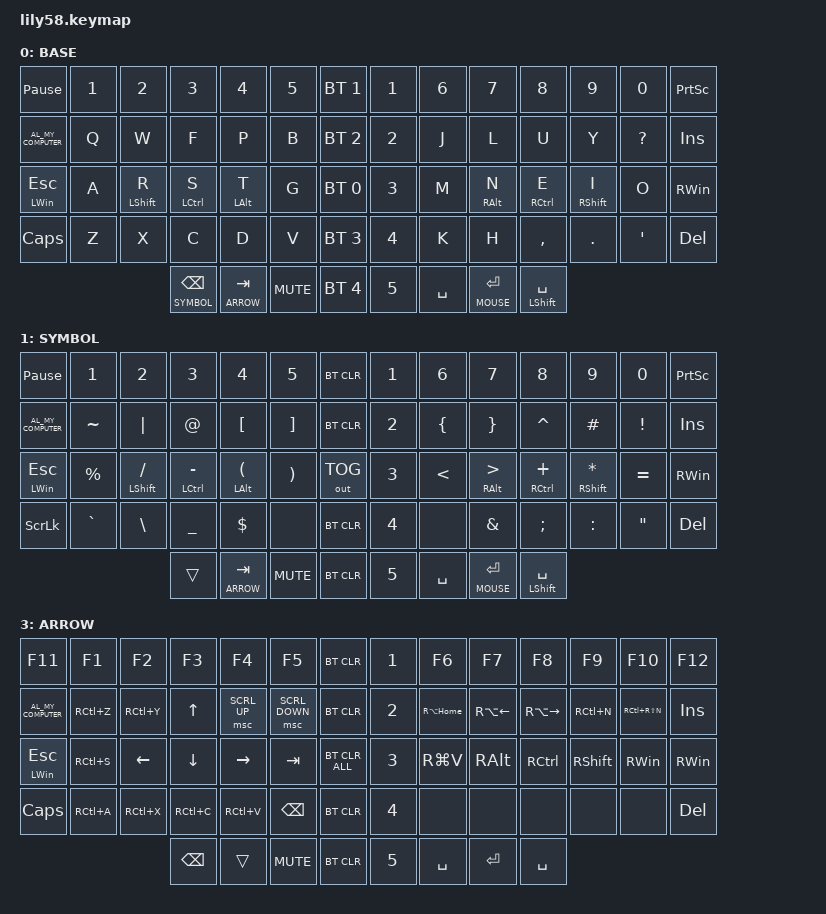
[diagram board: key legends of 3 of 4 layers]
#include <behaviors.dtsi>
#include <dt-bindings/zmk/keys.h>
#include <dt-bindings/zmk/bt.h>
#include <dt-bindings/zmk/rgb.h>
#include <dt-bindings/zmk/ext_power.h>
#include <dt-bindings/zmk/mouse.h>
#include <behaviors/mouse_keys.dtsi>
#include <dt-bindings/zmk/outputs.h>

&mmv {
  acceleration-exponent = <1>;      // 1
  time-to-max-speed-ms = <500>;    // 40
  delay-ms = <0>;                   // 0
};
&msc {
  acceleration-exponent = <1>;      // 0
  time-to-max-speed-ms = <40>;      // 500
  delay-ms = <0>;                   // 10
};

#define BASE 0
#define SYMBOL 1
#define MOUSE 2
#define ARROW 3


&lt {
    tapping-term-ms = <200>;
    quick-tap-ms = <200>;
};
&mt {
    tapping-term-ms = <400>;
    quick-tap-ms = <200>;
};




/ {
    keymap {
        compatible = "zmk,keymap";


        default_layer {
        display-name = "BASE";
            bindings = <
&kp PAUSE_BREAK          &kp N1     &kp N2             &kp N3                &kp N4             &kp N5       &bt BT_SEL 1                &kp N1        &kp N6       &kp N7                &kp N8                 &kp N9             &kp N0            &kp PRINTSCREEN
&kp C_AL_MY_COMPUTER     &kp Q      &kp W              &kp F                 &kp P              &kp B        &bt BT_SEL 2                &kp N2        &kp J        &kp L                 &kp U                  &kp Y              &kp QMARK         &kp INS
&mt LEFT_WIN ESC         &kp A      &mt LEFT_SHIFT R   &mt LCTRL S           &mt LEFT_ALT T     &kp G        &bt BT_SEL 0                &kp N3        &kp M        &mt RIGHT_ALT N       &mt RCTRL E            &mt RIGHT_SHIFT I  &kp O             &kp RIGHT_WIN
&kp CAPS                 &kp Z      &kp X              &kp C                 &kp D              &kp V        &bt BT_SEL 3                &kp N4        &kp K        &kp H                 &kp COMMA              &kp DOT            &kp SINGLE_QUOTE  &kp DEL
                                                       &lt SYMBOL BACKSPACE  &lt ARROW TAB      &kp C_MUTE   &bt BT_SEL 4                &kp N5        &kp SPACE    &lt MOUSE ENTER       &mt LEFT_SHIFT SPACE 
            >;
            sensor-bindings =
                <&inc_dec_kp C_VOL_DN C_VOL_UP>,
                <&inc_dec_kp RIGHT_ARROW LEFT_ARROW>;
        };



        lower_layer {
        display-name = "SYMBOL";
            bindings = <
&kp PAUSE_BREAK          &kp N1     &kp N2               &kp N3               &kp N4             &kp N5       &bt BT_CLR                &kp N1      &kp N6       &kp N7                &kp N8            &kp N9                &kp N0             &kp PRINTSCREEN
&kp C_AL_MY_COMPUTER     &kp TILDE  &kp PIPE             &kp AT               &kp LBKT           &kp RBKT     &bt BT_CLR                &kp N2      &kp LBRC     &kp RBRC              &kp CARET         &kp POUND             &kp EXCL           &kp INS
&mt LEFT_WIN ESC         &kp PRCNT  &mt LEFT_SHIFT FSLH  &mt LCTRL MINUS      &mt LEFT_ALT LPAR  &kp RPAR     &out OUT_TOG              &kp N3      &kp LT       &mt RIGHT_ALT GT      &mt RCTRL PLUS    &mt RIGHT_SHIFT STAR  &kp EQUAL          &kp RIGHT_WIN
&kp SCROLLLOCK           &kp GRAVE  &kp BSLH             &kp UNDER            &kp DLLR           &none        &bt BT_CLR                &kp N4      &none        &kp AMPS              &kp SEMI          &kp COLON             &kp DOUBLE_QUOTES  &kp DELETE
                                                         &trans               &lt ARROW TAB      &kp C_MUTE   &bt BT_CLR                &kp N5      &kp SPACE    &lt MOUSE ENTER       &mt LEFT_SHIFT SPACE 
            >;
            sensor-bindings =
                <&inc_dec_kp C_VOL_DN C_VOL_UP>,
                <&inc_dec_kp RIGHT_ARROW LEFT_ARROW>;
        };



        raise_layer {
        display-name = "MOUSE";
            bindings = <
&kp F11                  &kp F1     &kp F2               &kp F3               &kp F4             &kp F5            &bt BT_CLR                &kp N1      &kp F6         &kp F7                &kp F8                &kp F9            &kp F10            &kp F12
&kp C_AL_MY_COMPUTER     &kp RC(Z)  &kp RC(Y)            &mmv MOVE_UP         &msc SCRL_UP       &msc SCRL_DOWN    &bt BT_CLR                &kp N2      &kp RA(HOME)   &kp RA(LEFT_ARROW)    &kp RA(RIGHT_ARROW)   &kp RC(N)         &kp RC(RS(N))      &kp INS
&mt LEFT_WIN ESC         &kp RC(S)  &mmv MOVE_LEFT       &mmv MOVE_DOWN       &mmv MOVE_RIGHT    &kp LA(ESC)       &bt BT_CLR_ALL            &kp N3      &kp RG(V)      &kp RIGHT_ALT         &kp RCTRL             &kp RIGHT_SHIFT   &kp RIGHT_WIN      &kp RIGHT_WIN
&kp SCROLLLOCK           &kp RC(A)  &kp RC(X)            &kp RC(C)            &kp RC(V)          &mkp MCLK         &bt BT_CLR                &kp N4      &none          &none                 &none                 &none             &kp DEL
                                                         &mkp LCLK            &mkp RCLK          &kp C_MUTE        &bt BT_CLR                &kp N5      &kp SPACE      &trans                &kp SPACE
            >;
            sensor-bindings =
                <&inc_dec_kp C_VOL_DN C_VOL_UP>,
                <&inc_dec_kp RIGHT_ARROW LEFT_ARROW>;
        };



        adjust_layer {
        display-name = "ARROW";
            bindings = <
&kp F11                  &kp F1     &kp F2               &kp F3               &kp F4             &kp F5            &bt BT_CLR                &kp N1      &kp F6         &kp F7                &kp F8                &kp F9            &kp F10            &kp F12
&kp C_AL_MY_COMPUTER     &kp RC(Z)  &kp RC(Y)            &kp UP               &msc SCRL_UP       &msc SCRL_DOWN    &bt BT_CLR                &kp N2      &kp RA(HOME)   &kp RA(LEFT)          &kp RA(RIGHT_ARROW)   &kp RC(N)         &kp RC(RS(N))      &kp INS
&mt LEFT_WIN ESC         &kp RC(S)  &kp LEFT_ARROW       &kp DOWN_ARROW       &kp RIGHT_ARROW    &kp TAB           &bt BT_CLR_ALL            &kp N3      &kp RG(V)      &kp RIGHT_ALT         &kp RCTRL             &kp RIGHT_SHIFT   &kp RIGHT_WIN      &kp RIGHT_WIN
&kp CAPS                 &kp RC(A)  &kp RC(X)            &kp RC(C)            &kp RC(V)          &kp BACKSPACE     &bt BT_CLR                &kp N4      &none          &none                 &none                 &none             &none              &kp DEL
                                                         &kp BACKSPACE        &trans             &kp C_MUTE        &bt BT_CLR                &kp N5      &kp SPACE      &kp ENTER             &kp SPACE
            >;
            sensor-bindings =
                <&inc_dec_kp C_VOL_DN C_VOL_UP>,
                <&inc_dec_kp RIGHT_ARROW LEFT_ARROW>;
        };
    };
};
